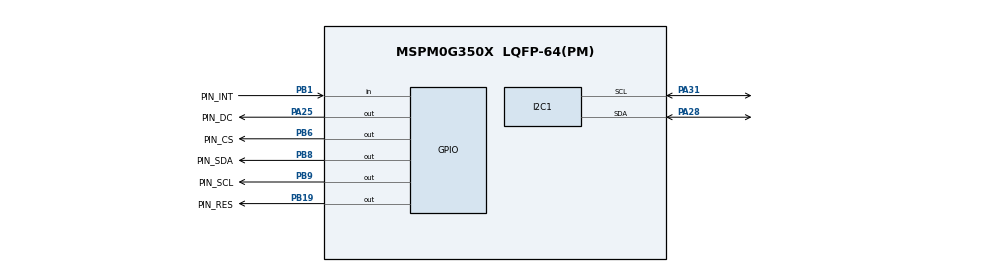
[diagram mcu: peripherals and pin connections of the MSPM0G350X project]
/**
 * @cliArgs --device "MSPM0G350X" --part "Default" --package "LQFP-64(PM)" --product "mspm0_sdk@2.04.00.06"
 * @versions {"tool":"1.23.0+4000"}
 */

/**
 * Import the modules used in this configuration.
 */
const GPIO   = scripting.addModule("/ti/driverlib/GPIO", {}, false);
const GPIO1  = GPIO.addInstance();
const GPIO2  = GPIO.addInstance();
const I2C    = scripting.addModule("/ti/driverlib/I2C", {}, false);
const I2C1   = I2C.addInstance();
const SYSCTL = scripting.addModule("/ti/driverlib/SYSCTL");

/**
 * Write custom configuration values to the imported modules.
 */
const divider7       = system.clockTree["PLL_PDIV"];
divider7.divideValue = 2;

const divider9       = system.clockTree["UDIV"];
divider9.divideValue = 2;

const multiplier2         = system.clockTree["PLL_QDIV"];
multiplier2.multiplyValue = 5;

const mux8       = system.clockTree["HSCLKMUX"];
mux8.inputSelect = "HSCLKMUX_SYSPLL2X";

GPIO1.$name                               = "GPIO_MPU6050";
GPIO1.associatedPins[0].$name             = "PIN_INT";
GPIO1.associatedPins[0].direction         = "INPUT";
GPIO1.associatedPins[0].internalResistor  = "PULL_UP";
GPIO1.associatedPins[0].interruptEn       = true;
GPIO1.associatedPins[0].interruptPriority = "1";
GPIO1.associatedPins[0].polarity          = "FALL";
GPIO1.associatedPins[0].pin.$assign       = "PB1";

const Board = scripting.addModule("/ti/driverlib/Board", {}, false);

GPIO2.$name                         = "GPIO_OLED";
GPIO2.associatedPins.create(5);
GPIO2.associatedPins[0].$name       = "PIN_RES";
GPIO2.associatedPins[0].pin.$assign = "PB19";
GPIO2.associatedPins[1].$name       = "PIN_SCL";
GPIO2.associatedPins[1].pin.$assign = "PB9";
GPIO2.associatedPins[2].$name       = "PIN_SDA";
GPIO2.associatedPins[2].pin.$assign = "PB8";
GPIO2.associatedPins[3].$name       = "PIN_DC";
GPIO2.associatedPins[3].pin.$assign = "PA25";
GPIO2.associatedPins[4].$name       = "PIN_CS";
GPIO2.associatedPins[4].pin.$assign = "PB6";

I2C1.$name                             = "I2C_MPU6050";
I2C1.basicEnableController             = true;
I2C1.basicControllerStandardBusSpeed   = "Fast";
I2C1.peripheral.$assign                = "I2C0";
I2C1.peripheral.sdaPin.$assign         = "PA28";
I2C1.peripheral.sclPin.$assign         = "PA31";
I2C1.sdaPinConfig.$name                = "ti_driverlib_gpio_GPIOPinGeneric0";
I2C1.sdaPinConfig.hideOutputInversion  = scripting.forceWrite(false);
I2C1.sdaPinConfig.onlyInternalResistor = scripting.forceWrite(false);
I2C1.sdaPinConfig.passedPeripheralType = scripting.forceWrite("Digital");
I2C1.sclPinConfig.$name                = "ti_driverlib_gpio_GPIOPinGeneric1";
I2C1.sclPinConfig.hideOutputInversion  = scripting.forceWrite(false);
I2C1.sclPinConfig.onlyInternalResistor = scripting.forceWrite(false);
I2C1.sclPinConfig.passedPeripheralType = scripting.forceWrite("Digital");

SYSCTL.forceDefaultClkConfig = true;
SYSCTL.clockTreeEn           = true;
scripting.suppress("For best practices when the CPUCLK is running at 32MHz and above, clear the flash status bit using DL_FlashCTL_executeClearStatus\\(\\) before executing any flash operation\\. Otherwise there may be false positives\\.", SYSCTL);

/**
 * Pinmux solution for unlocked pins/peripherals. This ensures that minor changes to the automatic solver in a future
 * version of the tool will not impact the pinmux you originally saw.  These lines can be completely deleted in order to
 * re-solve from scratch.
 */
Board.peripheral.$suggestSolution          = "DEBUGSS";
Board.peripheral.swclkPin.$suggestSolution = "PA20";
Board.peripheral.swdioPin.$suggestSolution = "PA19";
